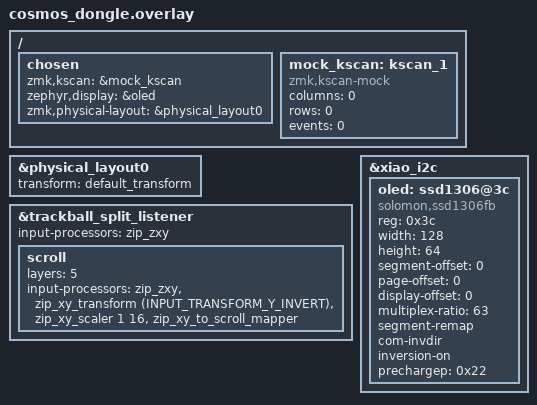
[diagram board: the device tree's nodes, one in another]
// Can't have the kscan0 here, that one's physical
/* 
    Central side is the only one that is aware of .keymap,
    so put all input processors you want to take effect in input listener here.
*/

#include "cosmos.dtsi"
#include "split_input.dtsi"
#include "cosmos-layouts.dtsi"
#include <input/processors.dtsi>
#include <input/processors/xyz.dtsi>
#include <dt-bindings/zmk/input_transform.h>
#include <behaviors/input_gestures_accel.dtsi>

&physical_layout0 {
    transform = <&default_transform>;
};

/* local trackball input split device child node, receiving events from the peripheral and raising them locally. */
// look into <split_input.dtsi> for mother node.
&trackball_split_listener {
	status = "okay";
    input-processors =
        <&zip_zxy>; // decompressor by badjeff
	scroll {
		layers = <5>; // SCROLL
		input-processors =
            <&zip_zxy>, // decompressor by badjeff
            <&zip_xy_transform (INPUT_TRANSFORM_Y_INVERT)>,
            <&zip_xy_scaler 1 16>,
            <&zip_xy_to_scroll_mapper>;
	};
};

/ {
    chosen {
        zmk,kscan = &mock_kscan;
        zephyr,display = &oled;
        zmk,physical-layout = &physical_layout0;
    };

    mock_kscan: kscan_1 {
        compatible = "zmk,kscan-mock";
        columns = <0>;
        rows = <0>;
        events = <0>;
    };
};

&xiao_i2c {
    status = "okay";
    
    oled: ssd1306@3c {
        compatible = "solomon,ssd1306fb";
        reg = <0x3c>;
        width = <128>;
        height = <64>;
        segment-offset = <0>;
        page-offset = <0>;
        display-offset = <0>;
        multiplex-ratio = <63>;
        segment-remap;
        com-invdir;
        inversion-on;
        prechargep = <0x22>;
    };
};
